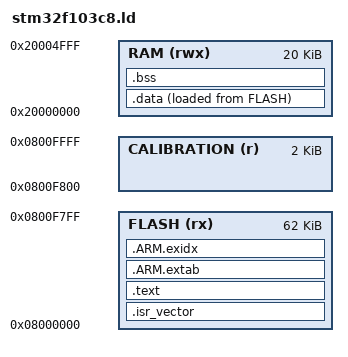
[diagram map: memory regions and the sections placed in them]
/* STM32F103C8: 62 KiB code, last two 1 KiB pages for calibration / 20 KiB RAM. */
ENTRY(Reset_Handler)
MEMORY
{
  FLASH (rx) : ORIGIN = 0x08000000, LENGTH = 62K
  CALIBRATION (r) : ORIGIN = 0x0800F800, LENGTH = 2K
  RAM (rwx) : ORIGIN = 0x20000000, LENGTH = 20K
}
_estack = ORIGIN(RAM) + LENGTH(RAM);
SECTIONS
{
  .isr_vector : { KEEP(*(.isr_vector)) } > FLASH
  .text : { *(.text*) *(.rodata*) . = ALIGN(4); } > FLASH
  .ARM.extab : { *(.ARM.extab*) } > FLASH
  .ARM.exidx : { *(.ARM.exidx*) } > FLASH
  _sidata = LOADADDR(.data);
  .data : { . = ALIGN(4); _sdata = .; *(.data*) . = ALIGN(4); _edata = .; } > RAM AT > FLASH
  .bss (NOLOAD) : { . = ALIGN(4); _sbss = .; *(.bss*) *(COMMON) . = ALIGN(4); _ebss = .; } > RAM
  ASSERT(_ebss <= _estack - 0x800, "Insufficient RAM for 2 KiB stack")
}
